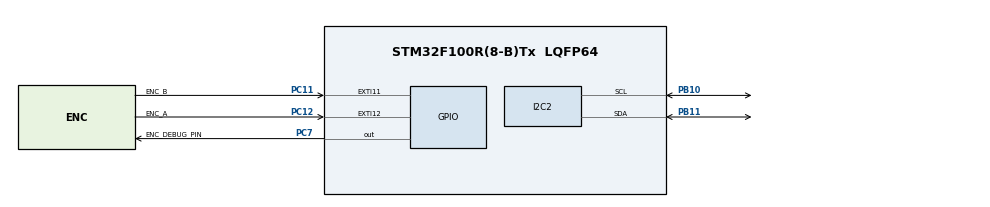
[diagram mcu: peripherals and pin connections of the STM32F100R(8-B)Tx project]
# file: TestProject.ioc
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Mcu.Family=STM32F1
Mcu.Name=STM32F100R(8-B)Tx
Mcu.Package=LQFP64
NVIC.EXTI15_10_IRQn=true\:0\:0\:false\:false\:true\:true
NVIC.FLASH_IRQn=true\:0\:0\:false\:false\:true\:true
NVIC.I2C2_EV_IRQn=true\:0\:0\:false\:false\:true\:true
NVIC.PriorityGroup=NVIC_PRIORITYGROUP_4
PA10.GPIO_Speed=GPIO_SPEED_FREQ_HIGH
PA10.Signal=S_TIM1_CH3
PA11.GPIO_Speed=GPIO_SPEED_FREQ_HIGH
PA11.Signal=S_TIM1_CH4
PB10.Mode=I2C
PB10.Signal=I2C2_SCL
PB11.Mode=I2C
PB11.Signal=I2C2_SDA
PC11.GPIO_Label=ENC_B
PC11.GPIO_ModeDefaultEXTI=GPIO_MODE_IT_RISING_FALLING
PC11.GPIO_PuPd=GPIO_PULLUP
PC11.Signal=GPXTI11
PC12.GPIO_Label=ENC_A
PC12.GPIO_ModeDefaultEXTI=GPIO_MODE_IT_RISING_FALLING
PC12.GPIO_PuPd=GPIO_PULLUP
PC12.Signal=GPXTI12
PC7.GPIO_Label=ENC_DEBUG_PIN
PC7.Signal=GPIO_Output
ProjectManager.HeapSize=0x200
ProjectManager.StackSize=0x400
ProjectManager.TargetToolchain=MDK-ARM V5
RCC.APB1Freq_Value=8000000
RCC.APB2Freq_Value=8000000
SH.S_TIM1_CH3.0=TIM1_CH3
SH.S_TIM1_CH4.0=TIM1_CH4
VP_SYS_VS_ND.Mode=No_Debug
VP_TIM6_VS_ClockSourceINT.Mode=Enable_Timer
board=custom

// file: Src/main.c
/**
  ******************************************************************************
  * @file           : main.c
  * @brief          : Main program body
  ******************************************************************************
  ** This notice applies to any and all portions of this file
  * that are not between comment pairs USER CODE BEGIN and
  * USER CODE END. Other portions of this file, whether
  * inserted by the user or by software development tools
  * are owned by their respective copyright owners.
  *
  * COPYRIGHT(c) 2018 STMicroelectronics
  *
  * Redistribution and use in source and binary forms, with or without modification,
  * are permitted provided that the following conditions are met:
  *   1. Redistributions of source code must retain the above copyright notice,
  *      this list of conditions and the following disclaimer.
  *   2. Redistributions in binary form must reproduce the above copyright notice,
  *      this list of conditions and the following disclaimer in the documentation
  *      and/or other materials provided with the distribution.
  *   3. Neither the name of STMicroelectronics nor the names of its contributors
  *      may be used to endorse or promote products derived from this software
  *      without specific prior written permission.
  *
  * THIS SOFTWARE IS PROVIDED BY THE COPYRIGHT HOLDERS AND CONTRIBUTORS "AS IS"
  * AND ANY EXPRESS OR IMPLIED WARRANTIES, INCLUDING, BUT NOT LIMITED TO, THE
  * IMPLIED WARRANTIES OF MERCHANTABILITY AND FITNESS FOR A PARTICULAR PURPOSE ARE
  * DISCLAIMED. IN NO EVENT SHALL THE COPYRIGHT HOLDER OR CONTRIBUTORS BE LIABLE
  * FOR ANY DIRECT, INDIRECT, INCIDENTAL, SPECIAL, EXEMPLARY, OR CONSEQUENTIAL
  * DAMAGES (INCLUDING, BUT NOT LIMITED TO, PROCUREMENT OF SUBSTITUTE GOODS OR
  * SERVICES; LOSS OF USE, DATA, OR PROFITS; OR BUSINESS INTERRUPTION) HOWEVER
  * CAUSED AND ON ANY THEORY OF LIABILITY, WHETHER IN CONTRACT, STRICT LIABILITY,
  * OR TORT (INCLUDING NEGLIGENCE OR OTHERWISE) ARISING IN ANY WAY OUT OF THE USE
  * OF THIS SOFTWARE, EVEN IF ADVISED OF THE POSSIBILITY OF SUCH DAMAGE.
  *
  ******************************************************************************
  */
#include "main.h"
#include "stm32f1xx_hal.h"

/* USER CODE BEGIN Includes */
#include "encoderCount.h"
/* USER CODE END Includes */

I2C_HandleTypeDef hi2c2;

TIM_HandleTypeDef htim6;

/* USER CODE BEGIN PV */
/* Private variables ---------------------------------------------------------*/

/* USER CODE END PV */

void SystemClock_Config(void);
static void MX_GPIO_Init(void);
static void MX_I2C2_Init(void);
static void MX_TIM6_Init(void);

/* USER CODE BEGIN PFP */
/* Private function prototypes -----------------------------------------------*/

/* USER CODE END PFP */

int main(void)
{

  /* MCU Configuration----------------------------------------------------------*/

  /* Reset of all peripherals, Initializes the Flash interface and the Systick. */
  HAL_Init();

  /* Configure the system clock */
  SystemClock_Config();

  /* Initialize all configured peripherals */
  MX_GPIO_Init();
  MX_I2C2_Init();
  MX_TIM6_Init();

  /* Infinite loop */
  /* USER CODE BEGIN WHILE */
	ENC_CNT_INIT();
	ENC_DEBUG_PIN_INIT();
  while (1)
  {

  /* USER CODE END WHILE */

  }

}

void SystemClock_Config(void)
{

  RCC_OscInitTypeDef RCC_OscInitStruct;
  RCC_ClkInitTypeDef RCC_ClkInitStruct;

    /**Initializes the CPU, AHB and APB busses clocks
    */
  RCC_OscInitStruct.OscillatorType = RCC_OSCILLATORTYPE_HSI;
  RCC_OscInitStruct.HSIState = RCC_HSI_ON;
  RCC_OscInitStruct.HSICalibrationValue = 16;
  RCC_OscInitStruct.PLL.PLLState = RCC_PLL_NONE;
  if (HAL_RCC_OscConfig(&RCC_OscInitStruct) != HAL_OK)
  {
    _Error_Handler(__FILE__, __LINE__);
  }

    /**Initializes the CPU, AHB and APB busses clocks
    */
  RCC_ClkInitStruct.ClockType = RCC_CLOCKTYPE_HCLK|RCC_CLOCKTYPE_SYSCLK
                              |RCC_CLOCKTYPE_PCLK1|RCC_CLOCKTYPE_PCLK2;
  RCC_ClkInitStruct.SYSCLKSource = RCC_SYSCLKSOURCE_HSI;
  RCC_ClkInitStruct.AHBCLKDivider = RCC_SYSCLK_DIV1;
  RCC_ClkInitStruct.APB1CLKDivider = RCC_HCLK_DIV1;
  RCC_ClkInitStruct.APB2CLKDivider = RCC_HCLK_DIV1;

  if (HAL_RCC_ClockConfig(&RCC_ClkInitStruct, FLASH_LATENCY_0) != HAL_OK)
  {
    _Error_Handler(__FILE__, __LINE__);
  }

    /**Configure the Systick interrupt time
    */
  HAL_SYSTICK_Config(HAL_RCC_GetHCLKFreq()/1000);

    /**Configure the Systick
    */
  HAL_SYSTICK_CLKSourceConfig(SYSTICK_CLKSOURCE_HCLK);

  /* SysTick_IRQn interrupt configuration */
  HAL_NVIC_SetPriority(SysTick_IRQn, 0, 0);
}

/* I2C2 init function */
static void MX_I2C2_Init(void)
{

  hi2c2.Instance = I2C2;
  hi2c2.Init.ClockSpeed = 100000;
  hi2c2.Init.DutyCycle = I2C_DUTYCYCLE_2;
  hi2c2.Init.OwnAddress1 = 0;
  hi2c2.Init.AddressingMode = I2C_ADDRESSINGMODE_7BIT;
  hi2c2.Init.DualAddressMode = I2C_DUALADDRESS_DISABLE;
  hi2c2.Init.OwnAddress2 = 0;
  hi2c2.Init.GeneralCallMode = I2C_GENERALCALL_DISABLE;
  hi2c2.Init.NoStretchMode = I2C_NOSTRETCH_DISABLE;
  if (HAL_I2C_Init(&hi2c2) != HAL_OK)
  {
    _Error_Handler(__FILE__, __LINE__);
  }

}

/* TIM6 init function */
static void MX_TIM6_Init(void)
{

  TIM_MasterConfigTypeDef sMasterConfig;

  htim6.Instance = TIM6;
  htim6.Init.Prescaler = 0;
  htim6.Init.CounterMode = TIM_COUNTERMODE_UP;
  htim6.Init.Period = 0;
  htim6.Init.AutoReloadPreload = TIM_AUTORELOAD_PRELOAD_DISABLE;
  if (HAL_TIM_Base_Init(&htim6) != HAL_OK)
  {
    _Error_Handler(__FILE__, __LINE__);
  }

  sMasterConfig.MasterOutputTrigger = TIM_TRGO_RESET;
  sMasterConfig.MasterSlaveMode = TIM_MASTERSLAVEMODE_DISABLE;
  if (HAL_TIMEx_MasterConfigSynchronization(&htim6, &sMasterConfig) != HAL_OK)
  {
    _Error_Handler(__FILE__, __LINE__);
  }

}

/** Configure pins as
        * Analog
        * Input
        * Output
        * EVENT_OUT
        * EXTI
     PA10   ------> S_TIM1_CH3
     PA11   ------> S_TIM1_CH4
*/
static void MX_GPIO_Init(void)
{

  GPIO_InitTypeDef GPIO_InitStruct;

  /* GPIO Ports Clock Enable */
  __HAL_RCC_GPIOB_CLK_ENABLE();
  __HAL_RCC_GPIOC_CLK_ENABLE();
  __HAL_RCC_GPIOA_CLK_ENABLE();

  /*Configure GPIO pin Output Level */
  HAL_GPIO_WritePin(ENC_DEBUG_PIN_GPIO_Port, ENC_DEBUG_PIN_Pin, GPIO_PIN_RESET);

  /*Configure GPIO pin : ENC_DEBUG_PIN_Pin */
  GPIO_InitStruct.Pin = ENC_DEBUG_PIN_Pin;
  GPIO_InitStruct.Mode = GPIO_MODE_OUTPUT_PP;
  GPIO_InitStruct.Pull = GPIO_NOPULL;
  GPIO_InitStruct.Speed = GPIO_SPEED_FREQ_LOW;
  HAL_GPIO_Init(ENC_DEBUG_PIN_GPIO_Port, &GPIO_InitStruct);

  /*Configure GPIO pins : PA10 PA11 */
  GPIO_InitStruct.Pin = GPIO_PIN_10|GPIO_PIN_11;
  GPIO_InitStruct.Mode = GPIO_MODE_AF_PP;
  GPIO_InitStruct.Speed = GPIO_SPEED_FREQ_HIGH;
  HAL_GPIO_Init(GPIOA, &GPIO_InitStruct);

  /*Configure GPIO pins : ENC_B_Pin ENC_A_Pin */
  GPIO_InitStruct.Pin = ENC_B_Pin|ENC_A_Pin;
  GPIO_InitStruct.Mode = GPIO_MODE_IT_RISING_FALLING;
  GPIO_InitStruct.Pull = GPIO_PULLUP;
  HAL_GPIO_Init(GPIOC, &GPIO_InitStruct);

  /* EXTI interrupt init*/
  HAL_NVIC_SetPriority(EXTI15_10_IRQn, 0, 0);
  HAL_NVIC_EnableIRQ(EXTI15_10_IRQn);

}

void _Error_Handler(char *file, int line)
{
  /* USER CODE BEGIN Error_Handler_Debug */
  /* User can add his own implementation to report the HAL error return state */
  while(1)
  {
    break;
  }
  /* USER CODE END Error_Handler_Debug */
}

/************************ (C) COPYRIGHT STMicroelectronics *****END OF FILE****/
